AUTOSAR XML (schema 4-0-3)
package /RcCar
  5 x sender receiver interface:
    IfWinker
      data state: type=IDT_Winker
    IfBuzzer
      data state: type=IDT_Buzzer
    IfLamp
      4 x data, all with type=IDT_Lamp:
        headlamp
        foglamp
        brakelamp
        backlamp
    IfDriving
      5 x data:
        angle: type=IDT_Angle
        speed: type=IDT_Speed
        steern: type=IDT_Adjust
        gain: type=IDT_Adjust
        brake: type=IDT_Brake
    IfBody
      5 x data, all with type=IDT_Lamp:
        headlamp
        foglamp
        hazard
        winker_r
        winker_l
  4 x client server interface:
    IfSteerAngle
      operation OpSetSteerAngle
        arg angle: type=IDT_Angle, direction=IN
    IfDriveSpeed
      operation OpSetDriveSpeed
        arg speed: type=IDT_Speed, direction=IN
    IfBrake
      operation OpSetBrake
        arg brake: type=IDT_Brake, direction=IN
    IfRCB3Command
      operation OpGetIfRCB3Command
        arg command: type=IDT_RCB3, direction=OUT
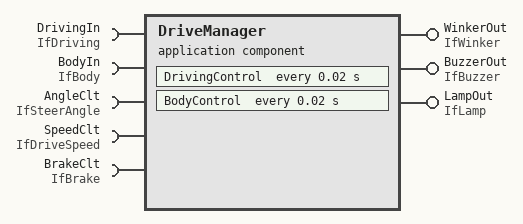
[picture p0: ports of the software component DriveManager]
  application sw component type DriveManager
    provide port WinkerOut: nonqueued-sender-com-spec{data-element=IfWinker/state, init-value=IDT_Winker:0}, provided-interface=IfWinker
    provide port BuzzerOut: nonqueued-sender-com-spec{data-element=IfBuzzer/state, init-value=IDT_Buzzer:0}, provided-interface=IfBuzzer
    provide port LampOut: provided-interface=IfLamp
      provided-com-specs:
        data-element=backlamp, init-value=IDT_Lamp:0
        data-element=brakelamp, init-value=IDT_Lamp:0
        data-element=IfLamp/headlamp, init-value=IDT_Lamp:0
        data-element=IfLamp/foglamp, init-value=IDT_Lamp:0
    5 x require port:
      DrivingIn: required-interface=IfDriving
        required-com-specs:
          data-element=brake, enable-update=true, handle-never-received=true, init-value=IDT_Brake:0
          data-element=angle, enable-update=true, handle-never-received=true, init-value=IDT_Angle:0
          data-element=gain, enable-update=true, handle-never-received=true, init-value=IDT_Adjust:0
          data-element=speed, enable-update=true, handle-never-received=true, init-value=IDT_Speed:0
          data-element=steern, enable-update=true, handle-never-received=true, init-value=IDT_Adjust:0
      BodyIn: required-interface=IfBody
        required-com-specs:
          data-element=IfBody/foglamp, enable-update=true, handle-never-received=true, init-value=IDT_Lamp:0
          data-element=hazard, enable-update=true, handle-never-received=true, init-value=IDT_Lamp:0
          data-element=IfBody/headlamp, enable-update=true, handle-never-received=true, init-value=IDT_Lamp:0
          data-element=winker_l, enable-update=true, handle-never-received=true, init-value=IDT_Lamp:0
          data-element=winker_r, enable-update=true, handle-never-received=true, init-value=IDT_Lamp:0
      AngleClt: required-interface=IfSteerAngle
      SpeedClt: required-interface=IfDriveSpeed
      BrakeClt: required-interface=IfBrake
    behavior IB_DM: handle-termination-and-restart=NO-SUPPORT
      timing event DrivingControl_timingEvent: start-on-event=DrivingControl, period=0.02
      timing event BodyControl_timingEvent: start-on-event=BodyControl, period=0.02
      runnable DrivingControl
        data-receive-point-by-arguments:
          5 x access:
            dataReceivePoint_DrivingControl_DrivingIn_angle: accessed-variable=DrivingIn.angle
            dataReceivePoint_DrivingControl_DrivingIn_speed: accessed-variable=DrivingIn.speed
            dataReceivePoint_DrivingControl_DrivingIn_steern: accessed-variable=DrivingIn.steern
            dataReceivePoint_DrivingControl_DrivingIn_gain: accessed-variable=DrivingIn.gain
            dataReceivePoint_DrivingControl_DrivingIn_brake: accessed-variable=DrivingIn.brake
        sync call serverCallPoint_DrivingControl_AngleClt_OpSetSteerAngle: operation=AngleClt.OpSetSteerAngle, timeout=0.0
        sync call serverCallPoint_DrivingControl_SpeedClt_OpSetDriveSpeed: operation=SpeedClt.OpSetDriveSpeed, timeout=0.0
        sync call serverCallPoint_DrivingControl_BrakeClt_OpSetBrake: operation=BrakeClt.OpSetBrake, timeout=0.0
      runnable BodyControl
        data-receive-point-by-arguments:
          5 x access:
            dataReceivePoint_BodyControl_BodyIn_headlamp: accessed-variable=BodyIn.headlamp
            dataReceivePoint_BodyControl_BodyIn_foglamp: accessed-variable=BodyIn.foglamp
            dataReceivePoint_BodyControl_BodyIn_hazard: accessed-variable=BodyIn.hazard
            dataReceivePoint_BodyControl_BodyIn_winker_r: accessed-variable=BodyIn.winker_r
            dataReceivePoint_BodyControl_BodyIn_winker_l: accessed-variable=BodyIn.winker_l
        data-send-points:
          6 x access:
            dataSendPoint_BodyControl_WinkerOut_state: accessed-variable=WinkerOut.state
            dataSendPoint_BodyControl_BuzzerOut_state: accessed-variable=BuzzerOut.state
            dataSendPoint_BodyControl_LampOut_headlamp: accessed-variable=LampOut.headlamp
            dataSendPoint_BodyControl_LampOut_foglamp: accessed-variable=LampOut.foglamp
            dataSendPoint_BodyControl_LampOut_brakelamp: accessed-variable=LampOut.brakelamp
            dataSendPoint_BodyControl_LampOut_backlamp: accessed-variable=LampOut.backlamp
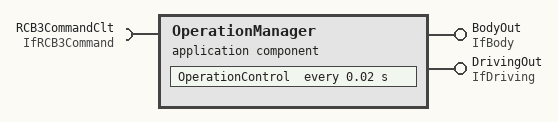
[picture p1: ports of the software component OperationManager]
  application sw component type OperationManager
    provide port BodyOut: provided-interface=IfBody
      provided-com-specs:
        data-element=IfBody/foglamp, init-value=IDT_Lamp:0
        data-element=hazard, init-value=IDT_Lamp:0
        data-element=IfBody/headlamp, init-value=IDT_Lamp:0
        data-element=winker_l, init-value=IDT_Lamp:0
        data-element=winker_r, init-value=IDT_Lamp:0
    provide port DrivingOut: provided-interface=IfDriving
      provided-com-specs:
        data-element=brake, init-value=IDT_Brake:0
        data-element=angle, init-value=IDT_Angle:0
        data-element=gain, init-value=IDT_Adjust:0
        data-element=speed, init-value=IDT_Speed:0
        data-element=steern, init-value=IDT_Adjust:0
    require port RCB3CommandClt: required-interface=IfRCB3Command
    behavior IB_CM: handle-termination-and-restart=NO-SUPPORT
      timing event OperationControl_timingEvent: start-on-event=OperationControl, period=0.02
      runnable OperationControl
        data-send-points:
          10 x access:
            dataSendPoint_OperationControl_DrivingOut_angle: accessed-variable=DrivingOut.angle
            dataSendPoint_OperationControl_DrivingOut_speed: accessed-variable=DrivingOut.speed
            dataSendPoint_OperationControl_DrivingOut_steern: accessed-variable=DrivingOut.steern
            dataSendPoint_OperationControl_DrivingOut_gain: accessed-variable=DrivingOut.gain
            dataSendPoint_OperationControl_DrivingOut_brake: accessed-variable=DrivingOut.brake
            dataSendPoint_OperationControl_BodyOut_headlamp: accessed-variable=BodyOut.headlamp
            dataSendPoint_OperationControl_BodyOut_foglamp: accessed-variable=BodyOut.foglamp
            dataSendPoint_OperationControl_BodyOut_hazard: accessed-variable=BodyOut.hazard
            dataSendPoint_OperationControl_BodyOut_winker_r: accessed-variable=BodyOut.winker_r
            dataSendPoint_OperationControl_BodyOut_winker_l: accessed-variable=BodyOut.winker_l
        sync call serverCallPoint_OperationControl_RCB3CommandClt_OpGetIfRCB3Command: operation=RCB3CommandClt.OpGetIfRCB3Command, timeout=0.0
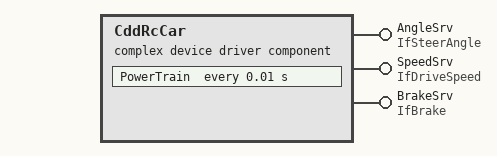
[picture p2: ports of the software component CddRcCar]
  complex device driver sw component type CddRcCar
    provide port AngleSrv: provided-interface=IfSteerAngle
    provide port SpeedSrv: provided-interface=IfDriveSpeed
    provide port BrakeSrv: provided-interface=IfBrake
    behavior IB_CR: handle-termination-and-restart=NO-SUPPORT
      timing event PowerTrain_timingEvent: start-on-event=PowerTrain, period=0.01
      operation invoked event AngleSrv_OpSetSteerAngle: start-on-event=SetSteerAngle, operation=AngleSrv.OpSetSteerAngle
      operation invoked event SpeedSrv_OpSetDriveSpeed: start-on-event=SetDriveSpeed, operation=SpeedSrv.OpSetDriveSpeed
      operation invoked event BrakeSrv_OpSetBrake: start-on-event=SetBrake, operation=BrakeSrv.OpSetBrake
      4 x runnable:
        PowerTrain
        SetSteerAngle
        SetDriveSpeed
        SetBrake
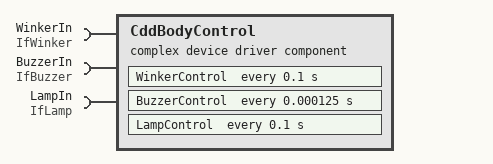
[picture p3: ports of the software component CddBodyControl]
  complex device driver sw component type CddBodyControl
    require port WinkerIn: nonqueued-receiver-com-spec{data-element=IfWinker/state, enable-update=true, handle-never-received=true, init-value=IDT_Winker:0}, required-interface=IfWinker
    require port BuzzerIn: nonqueued-receiver-com-spec{data-element=IfBuzzer/state, enable-update=true, handle-never-received=true, init-value=IDT_Buzzer:0}, required-interface=IfBuzzer
    require port LampIn: required-interface=IfLamp
      required-com-specs:
        data-element=backlamp, enable-update=true, handle-never-received=true, init-value=IDT_Lamp:0
        data-element=brakelamp, enable-update=true, handle-never-received=true, init-value=IDT_Lamp:0
        data-element=IfLamp/headlamp, enable-update=true, handle-never-received=true, init-value=IDT_Lamp:0
        data-element=IfLamp/foglamp, enable-update=true, handle-never-received=true, init-value=IDT_Lamp:0
    behavior IB_CBC: handle-termination-and-restart=NO-SUPPORT
      timing event WinkerControl_timingEvent: start-on-event=WinkerControl, period=0.1
      timing event BuzzerControl_timingEvent: start-on-event=BuzzerControl, period=0.000125
      timing event LampControl_timingEvent: start-on-event=LampControl, period=0.1
      runnable WinkerControl
        data-receive-point-by-arguments:
          access dataReceivePoint_WinkerControl_WinkerIn_state: accessed-variable=WinkerIn.state
      runnable BuzzerControl
        data-receive-point-by-arguments:
          access dataReceivePoint_BuzzerControl_BuzzerIn_state: accessed-variable=BuzzerIn.state
      runnable LampControl
        data-receive-point-by-arguments:
          4 x access:
            dataReceivePoint_LampControl_LampIn_headlamp: accessed-variable=LampIn.headlamp
            dataReceivePoint_LampControl_LampIn_foglamp: accessed-variable=LampIn.foglamp
            dataReceivePoint_LampControl_LampIn_brakelamp: accessed-variable=LampIn.brakelamp
            dataReceivePoint_LampControl_LampIn_backlamp: accessed-variable=LampIn.backlamp
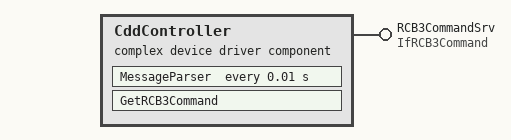
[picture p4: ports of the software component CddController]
  complex device driver sw component type CddController
    provide port RCB3CommandSrv: provided-interface=IfRCB3Command
    behavior IB_CC: handle-termination-and-restart=NO-SUPPORT
      exclusive area EaRCB3CommandGotFlg
      exclusive area EaUartRx
      timing event MessageParser_timingEvent: start-on-event=MessageParser, period=0.01
      operation invoked event RCB3CommandSrv_OpGetIfRCB3Command: start-on-event=GetRCB3Command, operation=RCB3CommandSrv.OpGetIfRCB3Command
      runnable MessageParser: can-enter-exclusive-area=EaUartRx
      runnable GetRCB3Command: can-enter-exclusive-area=EaRCB3CommandGotFlg
  complex device driver sw component type CddLedBlinker
    behavior IB_CBL: handle-termination-and-restart=NO-SUPPORT
      timing event LedBlinker_timingEvent: start-on-event=LedBlinker, period=0.5
      runnable LedBlinker
  composition sw component type Composition_RcCar
    6 x component:
      DriveManager: type=DriveManager
      CddRcCar: type=CddRcCar
      CddBodyControl: type=CddBodyControl
      OperationManager: type=OperationManager
      CddController: type=CddController
      CddLedBlinker: type=CddLedBlinker
    connect CddRcCar.AngleSrv -> DriveManager.AngleClt
    connect CddRcCar.SpeedSrv -> DriveManager.SpeedClt
    connect CddRcCar.BrakeSrv -> DriveManager.BrakeClt
    connect DriveManager.BuzzerOut -> CddBodyControl.BuzzerIn
    connect DriveManager.LampOut -> CddBodyControl.LampIn
    connect DriveManager.WinkerOut -> CddBodyControl.WinkerIn
    connect OperationManager.DrivingOut -> DriveManager.DrivingIn
    connect OperationManager.BodyOut -> DriveManager.BodyIn
    connect CddController.RCB3CommandSrv -> OperationManager.RCB3CommandClt
